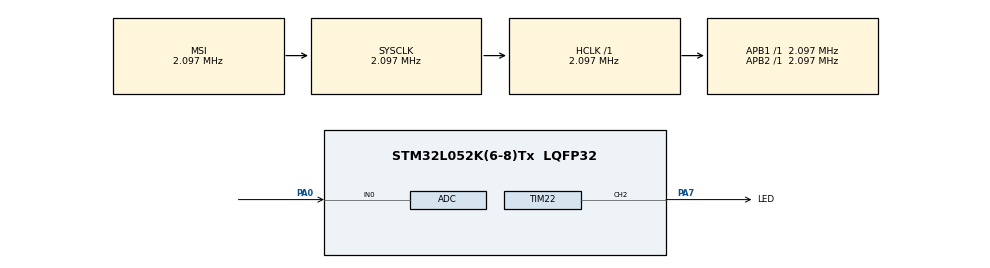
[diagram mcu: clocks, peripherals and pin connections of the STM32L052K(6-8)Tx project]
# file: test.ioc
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ADC.SamplingTime=ADC_SAMPLETIME_160CYCLES_5
Mcu.Family=STM32L0
Mcu.Name=STM32L052K(6-8)Tx
Mcu.Package=LQFP32
PA0.Mode=IN0
PA0.Signal=ADC_IN0
PA7.GPIO_Label=LED
PA7.Signal=S_TIM22_CH2
ProjectManager.HeapSize=0x200
ProjectManager.StackSize=0x400
ProjectManager.TargetToolchain=STM32CubeIDE
RCC.AHBFreq_Value=2097000
RCC.APB1Freq_Value=2097000
RCC.APB1TimFreq_Value=2097000
RCC.APB2Freq_Value=2097000
RCC.APB2TimFreq_Value=2097000
RCC.HSI16_VALUE=16000000
RCC.HSI48_VALUE=48000000
RCC.HSI_VALUE=16000000
RCC.LSE_VALUE=32768
RCC.MSI_VALUE=2097000
RCC.SYSCLKFreq_VALUE=2097000
RCC.VCOOutputFreq_Value=48000000
SH.S_TIM22_CH2.0=TIM22_CH2,PWM Generation2 CH2
TIM22.Channel-PWM\ Generation2\ CH2=TIM_CHANNEL_2
TIM22.Period=1000-1
TIM22.Prescaler=32-1
board=custom

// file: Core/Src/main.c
/* USER CODE BEGIN Header */
/**
 ******************************************************************************
 * @file           : main.c
 * @brief          : Main program body
 ******************************************************************************
 * @attention
 *
 * Copyright (c) 2022 STMicroelectronics.
 * All rights reserved.
 *
 * This software is licensed under terms that can be found in the LICENSE file
 * in the root directory of this software component.
 * If no LICENSE file comes with this software, it is provided AS-IS.
 *
 ******************************************************************************
 */
/* USER CODE END Header */
#include "main.h"

/* USER CODE BEGIN Includes */
#include <stdio.h>
#include <stdlib.h>
/* USER CODE END Includes */

/* USER CODE BEGIN PD */
#define NOW HAL_GetTick()
#define LED(N, X) HAL_GPIO_WritePin(LED_GPIO_Port, LED_Pin, X)
/* USER CODE END PD */

ADC_HandleTypeDef hadc;

TIM_HandleTypeDef htim22;

void SystemClock_Config(void);
static void MX_GPIO_Init(void);
static void MX_ADC_Init(void);
static void MX_TIM22_Init(void);

int main(void) {

	/* MCU Configuration--------------------------------------------------------*/

	/* Reset of all peripherals, Initializes the Flash interface and the Systick. */
	HAL_Init();

	/* Configure the system clock */
	SystemClock_Config();

	/* Initialize all configured peripherals */
	MX_GPIO_Init();
	MX_ADC_Init();
	MX_TIM22_Init();
	/* USER CODE BEGIN 2 */
	HAL_TIM_PWM_Start(&htim22, TIM_CHANNEL_2);
	/* USER CODE END 2 */

	/* Infinite loop */
	while (1) {

		/* USER CODE BEGIN 3 */
		HAL_ADC_Start(&hadc);
		HAL_ADC_PollForConversion(&hadc, 5);
		uint32_t vr = HAL_ADC_GetValue(&hadc);

		htim22.Instance->CCR2 = vr / 4;

		HAL_ADC_Stop(&hadc);
	}
	/* USER CODE END 3 */
}

void SystemClock_Config(void) {
	RCC_OscInitTypeDef RCC_OscInitStruct = { 0 };
	RCC_ClkInitTypeDef RCC_ClkInitStruct = { 0 };

	/** Configure the main internal regulator output voltage
	 */
	__HAL_PWR_VOLTAGESCALING_CONFIG(PWR_REGULATOR_VOLTAGE_SCALE1);

	/** Initializes the RCC Oscillators according to the specified parameters
	 * in the RCC_OscInitTypeDef structure.
	 */
	RCC_OscInitStruct.OscillatorType = RCC_OSCILLATORTYPE_MSI;
	RCC_OscInitStruct.MSIState = RCC_MSI_ON;
	RCC_OscInitStruct.MSICalibrationValue = 0;
	RCC_OscInitStruct.MSIClockRange = RCC_MSIRANGE_5;
	RCC_OscInitStruct.PLL.PLLState = RCC_PLL_NONE;
	if (HAL_RCC_OscConfig(&RCC_OscInitStruct) != HAL_OK) {
		Error_Handler();
	}

	/** Initializes the CPU, AHB and APB buses clocks
	 */
	RCC_ClkInitStruct.ClockType = RCC_CLOCKTYPE_HCLK | RCC_CLOCKTYPE_SYSCLK
			| RCC_CLOCKTYPE_PCLK1 | RCC_CLOCKTYPE_PCLK2;
	RCC_ClkInitStruct.SYSCLKSource = RCC_SYSCLKSOURCE_MSI;
	RCC_ClkInitStruct.AHBCLKDivider = RCC_SYSCLK_DIV1;
	RCC_ClkInitStruct.APB1CLKDivider = RCC_HCLK_DIV1;
	RCC_ClkInitStruct.APB2CLKDivider = RCC_HCLK_DIV1;

	if (HAL_RCC_ClockConfig(&RCC_ClkInitStruct, FLASH_LATENCY_0) != HAL_OK) {
		Error_Handler();
	}
}

static void MX_ADC_Init(void) {

	ADC_ChannelConfTypeDef sConfig = { 0 };

	/** Configure the global features of the ADC (Clock, Resolution, Data Alignment and number of conversion)
	 */
	hadc.Instance = ADC1;
	hadc.Init.OversamplingMode = DISABLE;
	hadc.Init.ClockPrescaler = ADC_CLOCK_SYNC_PCLK_DIV1;
	hadc.Init.Resolution = ADC_RESOLUTION_12B;
	hadc.Init.SamplingTime = ADC_SAMPLETIME_160CYCLES_5;
	hadc.Init.ScanConvMode = ADC_SCAN_DIRECTION_FORWARD;
	hadc.Init.DataAlign = ADC_DATAALIGN_RIGHT;
	hadc.Init.ContinuousConvMode = DISABLE;
	hadc.Init.DiscontinuousConvMode = DISABLE;
	hadc.Init.ExternalTrigConvEdge = ADC_EXTERNALTRIGCONVEDGE_NONE;
	hadc.Init.ExternalTrigConv = ADC_SOFTWARE_START;
	hadc.Init.DMAContinuousRequests = DISABLE;
	hadc.Init.EOCSelection = ADC_EOC_SINGLE_CONV;
	hadc.Init.Overrun = ADC_OVR_DATA_PRESERVED;
	hadc.Init.LowPowerAutoWait = DISABLE;
	hadc.Init.LowPowerFrequencyMode = ENABLE;
	hadc.Init.LowPowerAutoPowerOff = DISABLE;
	if (HAL_ADC_Init(&hadc) != HAL_OK) {
		Error_Handler();
	}

	/** Configure for the selected ADC regular channel to be converted.
	 */
	sConfig.Channel = ADC_CHANNEL_0;
	sConfig.Rank = ADC_RANK_CHANNEL_NUMBER;
	if (HAL_ADC_ConfigChannel(&hadc, &sConfig) != HAL_OK) {
		Error_Handler();
	}

}

static void MX_TIM22_Init(void) {

	TIM_MasterConfigTypeDef sMasterConfig = { 0 };
	TIM_OC_InitTypeDef sConfigOC = { 0 };

	htim22.Instance = TIM22;
	htim22.Init.Prescaler = 32 - 1;
	htim22.Init.CounterMode = TIM_COUNTERMODE_UP;
	htim22.Init.Period = 1000 - 1;
	htim22.Init.ClockDivision = TIM_CLOCKDIVISION_DIV1;
	htim22.Init.AutoReloadPreload = TIM_AUTORELOAD_PRELOAD_DISABLE;
	if (HAL_TIM_PWM_Init(&htim22) != HAL_OK) {
		Error_Handler();
	}
	sMasterConfig.MasterOutputTrigger = TIM_TRGO_RESET;
	sMasterConfig.MasterSlaveMode = TIM_MASTERSLAVEMODE_DISABLE;
	if (HAL_TIMEx_MasterConfigSynchronization(&htim22, &sMasterConfig)
			!= HAL_OK) {
		Error_Handler();
	}
	sConfigOC.OCMode = TIM_OCMODE_PWM1;
	sConfigOC.Pulse = 0;
	sConfigOC.OCPolarity = TIM_OCPOLARITY_HIGH;
	sConfigOC.OCFastMode = TIM_OCFAST_DISABLE;
	if (HAL_TIM_PWM_ConfigChannel(&htim22, &sConfigOC, TIM_CHANNEL_2)
			!= HAL_OK) {
		Error_Handler();
	}
	HAL_TIM_MspPostInit(&htim22);

}

static void MX_GPIO_Init(void) {

	/* GPIO Ports Clock Enable */
	__HAL_RCC_GPIOA_CLK_ENABLE();

}

void Error_Handler(void) {
	__disable_irq();
	while (1) {
	}
}
